AUTOSAR XML (schema 4-0-3)
package /Svc_CanTp
  impl type CanTp_PduIdType: category=VALUE, base-type=uint16
  impl type CanTp_TPParameterType: category=VALUE, base-type=uint8, compu {1=TP_BS, 0=TP_STMIN}
  client server interface CanTp_ChangeParameter: is-service=true, service-kind=ANY-STANDARDIZED
    operation ChangeParameter: possible-error=CanTp_ChangeParameter/E_NOT_OK
      arg id: type=CanTp_PduIdType, direction=IN
      arg parameter: type=CanTp_TPParameterType, direction=IN
      arg value: type=uint16, direction=IN
    error E_NOT_OK: error-code=1
  client server interface CanTp_ReadParameter: is-service=true, service-kind=ANY-STANDARDIZED
    operation ReadParameter: possible-error=CanTp_ReadParameter/E_NOT_OK
      arg id: type=CanTp_PduIdType, direction=IN
      arg parameter: type=CanTp_TPParameterType, direction=IN
      arg value: type=uint16, direction=OUT
    error E_NOT_OK: error-code=1
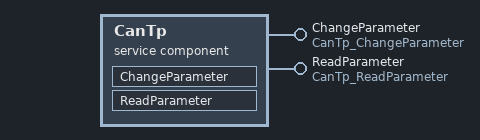
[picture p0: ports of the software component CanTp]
  service sw component type CanTp
    provide port ChangeParameter: server-com-spec{operation=ChangeParameter, queue-length=1}, provided-interface=CanTp_ChangeParameter
    provide port ReadParameter: server-com-spec{operation=ReadParameter, queue-length=1}, provided-interface=CanTp_ReadParameter
    behavior SwcIB_CanTp
      operation invoked event OIE_ChangeParameter: start-on-event=ChangeParameter, operation=ChangeParameter.ChangeParameter
      operation invoked event OIE_ReadParameter: start-on-event=ReadParameter, operation=ReadParameter.ReadParameter
      runnable ChangeParameter: arguments=[symbol=id, symbol=parameter, symbol=value], can-be-invoked-concurrently=true, symbol=CanTp_ChangeParameter
      runnable ReadParameter: arguments=[symbol=id, symbol=parameter, symbol=value], can-be-invoked-concurrently=true, symbol=CanTp_ReadParameter
  swc implementation SwcImplementation_Cantp: swc-bsw-mapping=SwcBswMapping_CanTp, behavior=SwcIB_CanTp
